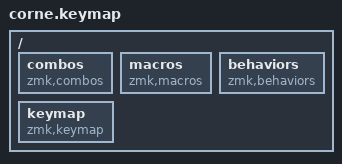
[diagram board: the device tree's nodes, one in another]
#include <dt-bindings/zmk/keys.h>
#include <dt-bindings/zmk/bt.h>
#include <dt-bindings/zmk/outputs.h>
#include <dt-bindings/zmk/ext_power.h>
#include <behaviors.dtsi>
#include "behaviors/_mt.dtsi"
#include "behaviors/_sk.dtsi"
#include "behaviors/_caps_word.dtsi"
/* #include "displays/_i2c1.dtsi" */

#define ZMK_POINTING_DEFAULT_MOVE_VAL 1800
#include <dt-bindings/zmk/pointing.h>

#define ALPHA_STRDY          0
#define NUMBERS              1
#define SYMBOLS              2
#define NAVIGATION_KEYS      3
#define NAVIGATION_VIM       4
#define NAVIGATION_WINDOWS   5
#define SYSTEM               6
#define MOUSE                7
#define MOUSE_SLOW           8
#define MOUSE_CLICKS         9
#define MACROPAD            10 


/ {
    combos {
        compatible = "zmk,combos";
        #include "combos/combos.dtsi"
    };
    /* zmk,display { */
    /*     compatible = "zmk,display-status-screen"; */
    /*     #include "displays/layout.dtsi"; */
    /* }; */
    macros {
        compatible="zmk,macros";
        #include "macros/init.dtsi"
    };
    behaviors {
        compatible = "zmk,behaviors";
        #include "behaviors/init.dtsi"
    };
    keymap {
        compatible = "zmk,keymap";
        #include "layers/alpha_strdy.dtsi"
        #include "layers/numbers.dtsi"
        #include "layers/symbols.dtsi"
        #include "layers/navigation_keys.dtsi"
        #include "layers/navigation_vim.dtsi"
        #include "layers/navigation_windows.dtsi"
        #include "layers/system.dtsi"
        #include "layers/mouse.dtsi"
        #include "layers/mouse_slow.dtsi"
        #include "layers/mouse_clicks.dtsi"
        #include "layers/macropad.dtsi"
    };
};

